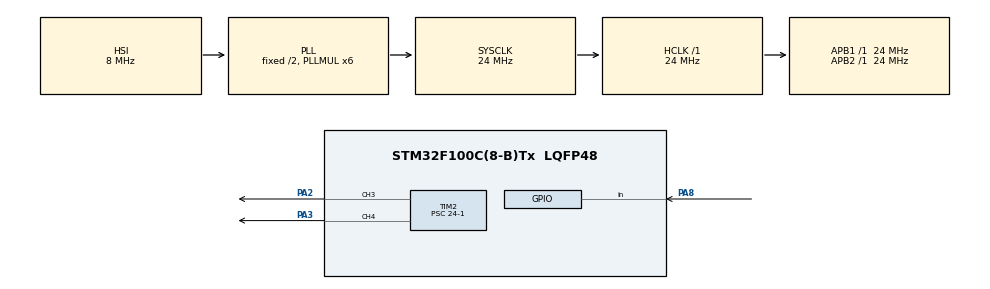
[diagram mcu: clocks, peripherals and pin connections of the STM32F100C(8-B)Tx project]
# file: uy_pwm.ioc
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Mcu.Family=STM32F1
Mcu.Name=STM32F100C(8-B)Tx
Mcu.Package=LQFP48
NVIC.PriorityGroup=NVIC_PRIORITYGROUP_4
PA13.Mode=Serial_Wire
PA13.Signal=SYS_JTMS-SWDIO
PA14.Mode=Serial_Wire
PA14.Signal=SYS_JTCK-SWCLK
PA2.Signal=S_TIM2_CH3
PA3.Signal=S_TIM2_CH4
PA8.GPIO_PuPd=GPIO_PULLUP
PA8.Signal=GPIO_Input
PD0-OSC_IN.Mode=HSE-External-Oscillator
PD0-OSC_IN.Signal=RCC_OSC_IN
PD1-OSC_OUT.Mode=HSE-External-Oscillator
PD1-OSC_OUT.Signal=RCC_OSC_OUT
ProjectManager.HeapSize=0x200
ProjectManager.StackSize=0x400
ProjectManager.TargetToolchain=STM32CubeIDE
RCC.AHBFreq_Value=24000000
RCC.APB1Freq_Value=24000000
RCC.APB1TimFreq_Value=24000000
RCC.APB2Freq_Value=24000000
RCC.APB2TimFreq_Value=24000000
RCC.HCLKFreq_Value=24000000
RCC.PLLMUL=RCC_PLL_MUL6
RCC.SYSCLKFreq_VALUE=24000000
RCC.SYSCLKSource=RCC_SYSCLKSOURCE_PLLCLK
SH.S_TIM2_CH3.0=TIM2_CH3,PWM Generation3 CH3
SH.S_TIM2_CH4.0=TIM2_CH4,PWM Generation4 CH4
TIM2.Channel-PWM\ Generation3\ CH3=TIM_CHANNEL_3
TIM2.Channel-PWM\ Generation4\ CH4=TIM_CHANNEL_4
TIM2.Period=1000-1
TIM2.Prescaler=24-1
VP_TIM2_VS_ClockSourceINT.Mode=Internal
board=custom

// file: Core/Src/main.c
/* USER CODE BEGIN Header */
/**
  ******************************************************************************
  * @file           : main.c
  * @brief          : Main program body
  ******************************************************************************
  * @attention
  *
  * Copyright (c) 2023 STMicroelectronics.
  * All rights reserved.
  *
  * This software is licensed under terms that can be found in the LICENSE file
  * in the root directory of this software component.
  * If no LICENSE file comes with this software, it is provided AS-IS.
  *
  ******************************************************************************
  */
/* USER CODE END Header */
#include "main.h"

TIM_HandleTypeDef htim2;

/* USER CODE BEGIN PV */
uint8_t up, s1;
uint16_t manual_rpm;

/* USER CODE END PV */

void SystemClock_Config(void);
static void MX_GPIO_Init(void);
static void MX_TIM2_Init(void);

/* USER CODE BEGIN 0 */
void driveSpeed(int dir , int pwmVal){
	if (dir == -1){
		__HAL_TIM_SET_COMPARE(&htim2, TIM_CHANNEL_3, pwmVal);
		__HAL_TIM_SET_COMPARE(&htim2, TIM_CHANNEL_4, 0);
	}
	else if (dir == 1){
		__HAL_TIM_SET_COMPARE(&htim2, TIM_CHANNEL_3, 0);
		__HAL_TIM_SET_COMPARE(&htim2, TIM_CHANNEL_4, pwmVal);
	}
	else{
		__HAL_TIM_SET_COMPARE(&htim2, TIM_CHANNEL_3, 0);
		__HAL_TIM_SET_COMPARE(&htim2, TIM_CHANNEL_4, 0);
	}
}

void upHandle(void){
	driveSpeed(-1, 300);
	while(1){
	  if(HAL_GPIO_ReadPin(GPIOA, GPIO_PIN_8) == 0){
		  driveSpeed(1, 0);
		  up = 0;
		  return;
	  }
	}
}

/* USER CODE END 0 */

int main(void)
{

  /* MCU Configuration--------------------------------------------------------*/

  /* Reset of all peripherals, Initializes the Flash interface and the Systick. */
  HAL_Init();

  /* Configure the system clock */
  SystemClock_Config();

  /* Initialize all configured peripherals */
  MX_GPIO_Init();
  MX_TIM2_Init();
  HAL_TIM_PWM_Start(&htim2,TIM_CHANNEL_3);
  HAL_TIM_PWM_Start(&htim2,TIM_CHANNEL_4);

  /* Infinite loop */
  /* USER CODE BEGIN WHILE */
  while (1)
  {
	  s1 = HAL_GPIO_ReadPin(GPIOA, GPIO_PIN_8);
	  if (up == 1){
		  upHandle();
	  }

	  if (up == 2){
		  driveSpeed(1, manual_rpm);
	  }
    /* USER CODE END WHILE */

  }
}

void SystemClock_Config(void)
{
  RCC_OscInitTypeDef RCC_OscInitStruct = {0};
  RCC_ClkInitTypeDef RCC_ClkInitStruct = {0};

  /** Initializes the RCC Oscillators according to the specified parameters
  * in the RCC_OscInitTypeDef structure.
  */
  RCC_OscInitStruct.OscillatorType = RCC_OSCILLATORTYPE_HSI;
  RCC_OscInitStruct.HSIState = RCC_HSI_ON;
  RCC_OscInitStruct.HSICalibrationValue = RCC_HSICALIBRATION_DEFAULT;
  RCC_OscInitStruct.PLL.PLLState = RCC_PLL_ON;
  RCC_OscInitStruct.PLL.PLLSource = RCC_PLLSOURCE_HSI_DIV2;
  RCC_OscInitStruct.PLL.PLLMUL = RCC_PLL_MUL6;
  if (HAL_RCC_OscConfig(&RCC_OscInitStruct) != HAL_OK)
  {
    Error_Handler();
  }

  /** Initializes the CPU, AHB and APB buses clocks
  */
  RCC_ClkInitStruct.ClockType = RCC_CLOCKTYPE_HCLK|RCC_CLOCKTYPE_SYSCLK
                              |RCC_CLOCKTYPE_PCLK1|RCC_CLOCKTYPE_PCLK2;
  RCC_ClkInitStruct.SYSCLKSource = RCC_SYSCLKSOURCE_PLLCLK;
  RCC_ClkInitStruct.AHBCLKDivider = RCC_SYSCLK_DIV1;
  RCC_ClkInitStruct.APB1CLKDivider = RCC_HCLK_DIV1;
  RCC_ClkInitStruct.APB2CLKDivider = RCC_HCLK_DIV1;

  if (HAL_RCC_ClockConfig(&RCC_ClkInitStruct, FLASH_LATENCY_0) != HAL_OK)
  {
    Error_Handler();
  }
}

static void MX_TIM2_Init(void)
{

  TIM_ClockConfigTypeDef sClockSourceConfig = {0};
  TIM_MasterConfigTypeDef sMasterConfig = {0};
  TIM_OC_InitTypeDef sConfigOC = {0};

  htim2.Instance = TIM2;
  htim2.Init.Prescaler = 24-1;
  htim2.Init.CounterMode = TIM_COUNTERMODE_UP;
  htim2.Init.Period = 1000-1;
  htim2.Init.ClockDivision = TIM_CLOCKDIVISION_DIV1;
  htim2.Init.AutoReloadPreload = TIM_AUTORELOAD_PRELOAD_DISABLE;
  if (HAL_TIM_Base_Init(&htim2) != HAL_OK)
  {
    Error_Handler();
  }
  sClockSourceConfig.ClockSource = TIM_CLOCKSOURCE_INTERNAL;
  if (HAL_TIM_ConfigClockSource(&htim2, &sClockSourceConfig) != HAL_OK)
  {
    Error_Handler();
  }
  if (HAL_TIM_PWM_Init(&htim2) != HAL_OK)
  {
    Error_Handler();
  }
  sMasterConfig.MasterOutputTrigger = TIM_TRGO_RESET;
  sMasterConfig.MasterSlaveMode = TIM_MASTERSLAVEMODE_DISABLE;
  if (HAL_TIMEx_MasterConfigSynchronization(&htim2, &sMasterConfig) != HAL_OK)
  {
    Error_Handler();
  }
  sConfigOC.OCMode = TIM_OCMODE_PWM1;
  sConfigOC.Pulse = 0;
  sConfigOC.OCPolarity = TIM_OCPOLARITY_HIGH;
  sConfigOC.OCFastMode = TIM_OCFAST_DISABLE;
  if (HAL_TIM_PWM_ConfigChannel(&htim2, &sConfigOC, TIM_CHANNEL_3) != HAL_OK)
  {
    Error_Handler();
  }
  if (HAL_TIM_PWM_ConfigChannel(&htim2, &sConfigOC, TIM_CHANNEL_4) != HAL_OK)
  {
    Error_Handler();
  }
  HAL_TIM_MspPostInit(&htim2);

}

static void MX_GPIO_Init(void)
{
  GPIO_InitTypeDef GPIO_InitStruct = {0};

  /* GPIO Ports Clock Enable */
  __HAL_RCC_GPIOD_CLK_ENABLE();
  __HAL_RCC_GPIOA_CLK_ENABLE();

  /*Configure GPIO pin : PA8 */
  GPIO_InitStruct.Pin = GPIO_PIN_8;
  GPIO_InitStruct.Mode = GPIO_MODE_INPUT;
  GPIO_InitStruct.Pull = GPIO_PULLUP;
  HAL_GPIO_Init(GPIOA, &GPIO_InitStruct);

}

void Error_Handler(void)
{
  __disable_irq();
  while (1)
  {
  }
}
